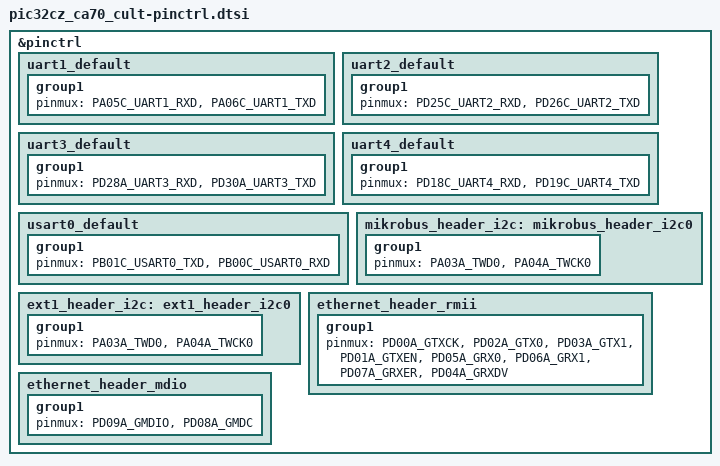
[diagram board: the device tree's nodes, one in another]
/*
 * SPDX-FileCopyrightText: Copyright (c) 2026 Microchip Technology Inc.
 *
 * SPDX-License-Identifier: Apache-2.0
 */

#include <dt-bindings/pic32c/pic32cz_ca/pic32cz_ca70/pic32cz2051ca70144-pinctrl.h>

&pinctrl {
	uart1_default: uart1_default {
		group1 {
			pinmux = <PA05C_UART1_RXD>,
				 <PA06C_UART1_TXD>;
		};
	};

	uart2_default: uart2_default {
		group1 {
			pinmux = <PD25C_UART2_RXD>,
				 <PD26C_UART2_TXD>;
		};
	};

	uart3_default: uart3_default {
		group1 {
			pinmux = <PD28A_UART3_RXD>,
				 <PD30A_UART3_TXD>;
		};
	};

	uart4_default: uart4_default {
		group1 {
			pinmux = <PD18C_UART4_RXD>,
				 <PD19C_UART4_TXD>;
		};
	};

	usart0_default: usart0_default {
		group1 {
			pinmux = <PB01C_USART0_TXD>,
				 <PB00C_USART0_RXD>;
		};
	};

	mikrobus_header_i2c: mikrobus_header_i2c0: mikrobus_header_i2c0 {
		group1 {
			pinmux = <PA03A_TWD0>,
				 <PA04A_TWCK0>;
		};
	};

	ext1_header_i2c: ext1_header_i2c0: ext1_header_i2c0 {
		group1 {
			pinmux = <PA03A_TWD0>,
				 <PA04A_TWCK0>;
		};
	};

	ethernet_header_rmii: ethernet_header_rmii {
		group1 {
			pinmux = <PD00A_GTXCK>,
				 <PD02A_GTX0>,
				 <PD03A_GTX1>,
				 <PD01A_GTXEN>,
				 <PD05A_GRX0>,
				 <PD06A_GRX1>,
				 <PD07A_GRXER>,
				 <PD04A_GRXDV>;
		};
	};

	ethernet_header_mdio: ethernet_header_mdio {
		group1 {
			pinmux = <PD09A_GMDIO>,
				 <PD08A_GMDC>;
		};
	};
};
